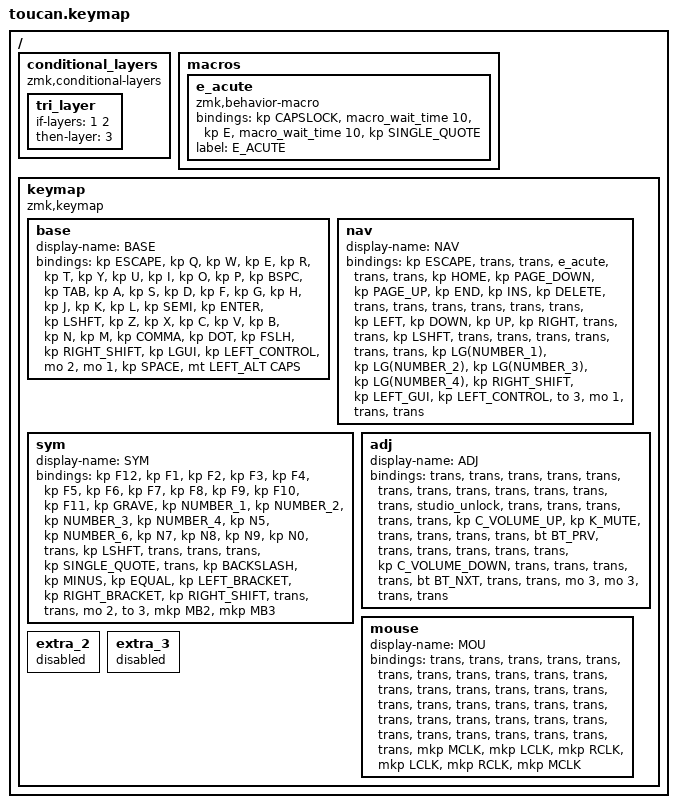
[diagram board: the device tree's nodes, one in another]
#include <behaviors.dtsi>
#include <dt-bindings/zmk/bt.h>
#include <dt-bindings/zmk/keys.h>
#include <dt-bindings/zmk/pointing.h>

#define BASE 0
#define NAV  1
#define SYM  2
#define ADJ  3

/ {
    conditional_layers {
        compatible = "zmk,conditional-layers";

        tri_layer {
            if-layers = <1 2>;
            then-layer = <3>;
        };
    };

    macros {
        e_acute: e_acute {
            compatible = "zmk,behavior-macro";
            #binding-cells = <0>;
            bindings =
                <&kp CAPSLOCK>,
                <&macro_wait_time 10>,
                <&kp E>,
                <&macro_wait_time 10>,
                <&kp SINGLE_QUOTE>;

            label = "E_ACUTE";
        };
    };

    keymap {
        compatible = "zmk,keymap";

        base {
            display-name = "BASE";
            bindings = <
&kp ESCAPE  &kp Q  &kp W  &kp E  &kp R  &kp T  &kp Y  &kp U  &kp I  &kp O  &kp P  &kp BSPC  &kp TAB  &kp A  &kp S  &kp D  &kp F  &kp G  &kp H  &kp J  &kp K  &kp L  &kp SEMI  &kp ENTER  &kp LSHFT  &kp Z  &kp X  &kp C  &kp V  &kp B  &kp N  &kp M  &kp COMMA  &kp DOT  &kp FSLH  &kp RIGHT_SHIFT  &kp LGUI  &kp LEFT_CONTROL  &mo 2  &mo 1  &kp SPACE  &mt LEFT_ALT CAPS
            >;
        };

        nav {
            display-name = "NAV";
            bindings = <
&kp ESCAPE  &trans  &trans  &e_acute  &trans  &trans  &kp HOME  &kp PAGE_DOWN  &kp PAGE_UP  &kp END  &kp INS  &kp DELETE  &trans  &trans  &trans  &trans  &trans  &trans  &kp LEFT  &kp DOWN  &kp UP  &kp RIGHT  &trans  &trans  &kp LSHFT  &trans  &trans  &trans  &trans  &trans  &trans  &kp LG(NUMBER_1)  &kp LG(NUMBER_2)  &kp LG(NUMBER_3)  &kp LG(NUMBER_4)  &kp RIGHT_SHIFT  &kp LEFT_GUI  &kp LEFT_CONTROL  &to 3  &mo 1  &trans  &trans
            >;
        };

        sym {
            display-name = "SYM";
            bindings = <
&kp F12  &kp F1  &kp F2  &kp F3  &kp F4  &kp F5  &kp F6  &kp F7  &kp F8  &kp F9  &kp F10  &kp F11  &kp GRAVE  &kp NUMBER_1  &kp NUMBER_2  &kp NUMBER_3  &kp NUMBER_4  &kp N5  &kp NUMBER_6  &kp N7  &kp N8  &kp N9  &kp N0  &trans  &kp LSHFT  &trans  &trans  &trans  &kp SINGLE_QUOTE  &trans  &kp BACKSLASH  &kp MINUS  &kp EQUAL  &kp LEFT_BRACKET  &kp RIGHT_BRACKET  &kp RIGHT_SHIFT  &trans  &trans  &mo 2  &to 3  &mkp MB2  &mkp MB3
            >;
        };

        adj {
            display-name = "ADJ";
            bindings = <
&trans  &trans  &trans  &trans  &trans  &trans  &trans  &trans  &trans  &trans  &trans  &trans  &studio_unlock  &trans  &trans  &trans  &trans  &trans  &kp C_VOLUME_UP  &kp K_MUTE  &trans  &trans  &trans  &trans  &bt BT_PRV  &trans  &trans  &trans  &trans  &trans  &kp C_VOLUME_DOWN  &trans  &trans  &trans  &trans  &bt BT_NXT  &trans  &trans  &mo 3  &mo 3  &trans  &trans
            >;
        };

        mouse {
            display-name = "MOU";
            bindings = <
&trans  &trans  &trans  &trans  &trans  &trans  &trans  &trans  &trans  &trans  &trans  &trans  &trans  &trans  &trans  &trans  &trans  &trans  &trans  &trans  &trans  &trans  &trans  &trans  &trans  &trans  &trans  &trans  &trans  &trans  &trans  &trans  &trans  &trans  &trans  &trans  &mkp MCLK  &mkp LCLK  &mkp RCLK  &mkp LCLK  &mkp RCLK  &mkp MCLK
            >;
        };

        extra_2 { status = "reserved"; };

        extra_3 { status = "reserved"; };
    };
};
